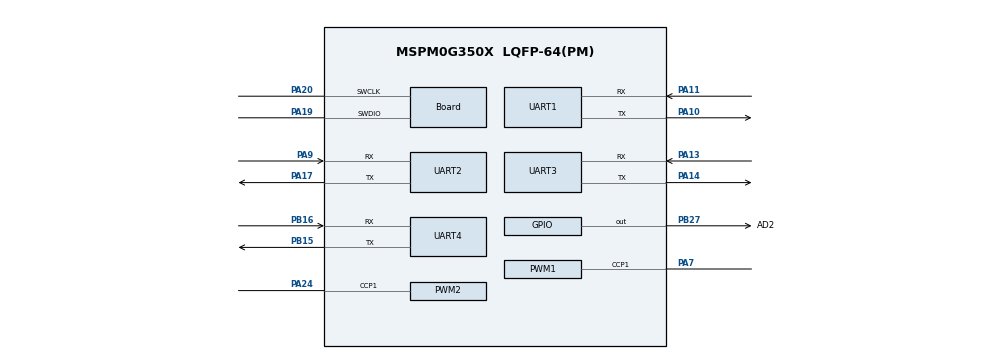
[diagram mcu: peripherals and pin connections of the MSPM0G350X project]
/**
 * @cliArgs --device "MSPM0G350X" --package "LQFP-64(PM)" --part "Default" --product "mspm0_sdk@1.30.00.03"
 * @versions {"tool":"1.19.0+3426"}
 */

/**
 * Import the modules used in this configuration.
 */
const ADC12         = scripting.addModule("/ti/driverlib/ADC12", {}, false);
const ADC121        = ADC12.addInstance();
const ADC122        = ADC12.addInstance();
const GPIO          = scripting.addModule("/ti/driverlib/GPIO", {}, false);
const GPIO1         = GPIO.addInstance();
const GPIO2         = GPIO.addInstance();
const GPIO3         = GPIO.addInstance();
const GPIO4         = GPIO.addInstance();
const GPIO5         = GPIO.addInstance();
const PWM           = scripting.addModule("/ti/driverlib/PWM", {}, false);
const PWM1          = PWM.addInstance();
const PWM2          = PWM.addInstance();
const SYSCTL        = scripting.addModule("/ti/driverlib/SYSCTL");
const SYSTICK       = scripting.addModule("/ti/driverlib/SYSTICK");
const TIMER         = scripting.addModule("/ti/driverlib/TIMER", {}, false);
const TIMER1        = TIMER.addInstance();
const TIMER2        = TIMER.addInstance();
const TIMER3        = TIMER.addInstance();
const TIMER4        = TIMER.addInstance();
const UART          = scripting.addModule("/ti/driverlib/UART", {}, false);
const UART1         = UART.addInstance();
const UART2         = UART.addInstance();
const UART3         = UART.addInstance();
const UART4         = UART.addInstance();
const ProjectConfig = scripting.addModule("/ti/project_config/ProjectConfig");

/**
 * Write custom configuration values to the imported modules.
 */
const divider6       = system.clockTree["PLL_CLK2X_DIV"];
divider6.divideValue = 4;

const divider7       = system.clockTree["PLL_PDIV"];
divider7.divideValue = 2;

const divider9       = system.clockTree["UDIV"];
divider9.divideValue = 2;

const multiplier2         = system.clockTree["PLL_QDIV"];
multiplier2.multiplyValue = 10;

const mux8       = system.clockTree["HSCLKMUX"];
mux8.inputSelect = "HSCLKMUX_SYSPLL2X";

ADC121.$name                             = "ADC_GRAY_SCALE";
ADC121.adcMem0_name                      = "ADC_CH0";
ADC121.sampClkDiv                        = "DL_ADC12_CLOCK_DIVIDE_8";
ADC121.repeatMode                        = true;
ADC121.sampleTime0                       = "3 ms";
ADC121.peripheral.$assign                = "ADC0";
ADC121.peripheral.adcPin0.$assign        = "PA27";
ADC121.adcPin0Config.hideOutputInversion = scripting.forceWrite(false);
ADC121.adcPin0Config.$name               = "ti_driverlib_gpio_GPIOPinGeneric8";

ADC122.adcMem0_name        = "ADC_CH0";
ADC122.sampClkDiv          = "DL_ADC12_CLOCK_DIVIDE_8";
ADC122.repeatMode          = true;
ADC122.$name               = "ADC_BUTTON";
ADC122.adcMem0chansel      = "DL_ADC12_INPUT_CHAN_8";
ADC122.peripheral.$assign  = "ADC1";
ADC122.adcPin8Config.$name = "ti_driverlib_gpio_GPIOPinGeneric4";

const Board                       = scripting.addModule("/ti/driverlib/Board", {}, false);
Board.peripheral.$assign          = "DEBUGSS";
Board.peripheral.swclkPin.$assign = "PA20";
Board.peripheral.swdioPin.$assign = "PA19";

GPIO1.$name                              = "REMINDER";
GPIO1.associatedPins.create(3);
GPIO1.associatedPins[0].$name            = "LED";
GPIO1.associatedPins[0].ioStructure      = "SD";
GPIO1.associatedPins[0].assignedPin      = "22";
GPIO1.associatedPins[0].assignedPort     = "PORTB";
GPIO1.associatedPins[0].internalResistor = "PULL_UP";
GPIO1.associatedPins[1].$name            = "BUZZ";
GPIO1.associatedPins[1].ioStructure      = "SD";
GPIO1.associatedPins[1].internalResistor = "PULL_UP";
GPIO1.associatedPins[1].assignedPort     = "PORTA";
GPIO1.associatedPins[1].assignedPin      = "29";
GPIO1.associatedPins[2].$name            = "LAZER";
GPIO1.associatedPins[2].ioStructure      = "SD";

GPIO2.port                               = "PORTB";
GPIO2.$name                              = "ENCODER_R";
GPIO2.associatedPins.create(2);
GPIO2.associatedPins[0].direction        = "INPUT";
GPIO2.associatedPins[0].ioStructure      = "SD";
GPIO2.associatedPins[0].interruptEn      = true;
GPIO2.associatedPins[0].internalResistor = "PULL_UP";
GPIO2.associatedPins[0].assignedPin      = "17";
GPIO2.associatedPins[0].polarity         = "RISE_FALL";
GPIO2.associatedPins[0].$name            = "R_A";
GPIO2.associatedPins[1].direction        = "INPUT";
GPIO2.associatedPins[1].ioStructure      = "SD";
GPIO2.associatedPins[1].interruptEn      = true;
GPIO2.associatedPins[1].internalResistor = "PULL_UP";
GPIO2.associatedPins[1].assignedPin      = "18";
GPIO2.associatedPins[1].polarity         = "RISE_FALL";
GPIO2.associatedPins[1].$name            = "R_B";

GPIO3.port                               = "PORTB";
GPIO3.$name                              = "ENCODER_L";
GPIO3.associatedPins.create(2);
GPIO3.associatedPins[0].direction        = "INPUT";
GPIO3.associatedPins[0].ioStructure      = "SD";
GPIO3.associatedPins[0].interruptEn      = true;
GPIO3.associatedPins[0].internalResistor = "PULL_UP";
GPIO3.associatedPins[0].assignedPin      = "21";
GPIO3.associatedPins[0].polarity         = "RISE_FALL";
GPIO3.associatedPins[0].$name            = "L_A";
GPIO3.associatedPins[1].direction        = "INPUT";
GPIO3.associatedPins[1].ioStructure      = "SD";
GPIO3.associatedPins[1].interruptEn      = true;
GPIO3.associatedPins[1].internalResistor = "PULL_UP";
GPIO3.associatedPins[1].assignedPin      = "11";
GPIO3.associatedPins[1].polarity         = "RISE_FALL";
GPIO3.associatedPins[1].$name            = "L_B";

GPIO4.$name                              = "MOTOR_DRV";
GPIO4.associatedPins.create(5);
GPIO4.associatedPins[0].ioStructure      = "SD";
GPIO4.associatedPins[0].internalResistor = "PULL_UP";
GPIO4.associatedPins[0].$name            = "STBY";
GPIO4.associatedPins[0].assignedPort     = "PORTB";
GPIO4.associatedPins[0].assignedPin      = "14";
GPIO4.associatedPins[1].ioStructure      = "SD";
GPIO4.associatedPins[1].internalResistor = "PULL_UP";
GPIO4.associatedPins[1].assignedPort     = "PORTB";
GPIO4.associatedPins[1].$name            = "L_IN1";
GPIO4.associatedPins[1].assignedPin      = "1";
GPIO4.associatedPins[2].ioStructure      = "SD";
GPIO4.associatedPins[2].internalResistor = "PULL_UP";
GPIO4.associatedPins[2].$name            = "L_IN2";
GPIO4.associatedPins[2].assignedPin      = "0";
GPIO4.associatedPins[2].assignedPort     = "PORTB";
GPIO4.associatedPins[3].ioStructure      = "SD";
GPIO4.associatedPins[3].internalResistor = "PULL_UP";
GPIO4.associatedPins[3].$name            = "R_IN1";
GPIO4.associatedPins[3].assignedPort     = "PORTA";
GPIO4.associatedPins[3].assignedPin      = "16";
GPIO4.associatedPins[4].ioStructure      = "SD";
GPIO4.associatedPins[4].internalResistor = "PULL_UP";
GPIO4.associatedPins[4].$name            = "R_IN2";
GPIO4.associatedPins[4].assignedPort     = "PORTB";
GPIO4.associatedPins[4].assignedPin      = "19";

GPIO5.$name                          = "GRAY_SCALE";
GPIO5.associatedPins.create(3);
GPIO5.associatedPins[0].$name        = "AD0";
GPIO5.associatedPins[0].assignedPort = "PORTB";
GPIO5.associatedPins[0].assignedPin  = "23";
GPIO5.associatedPins[1].$name        = "AD1";
GPIO5.associatedPins[1].assignedPort = "PORTB";
GPIO5.associatedPins[1].assignedPin  = "26";
GPIO5.associatedPins[2].$name        = "AD2";
GPIO5.associatedPins[2].assignedPort = "PORTB";
GPIO5.associatedPins[2].assignedPin  = "27";
GPIO5.associatedPins[2].pin.$assign  = "PB27";

PWM1.timerStartTimer                    = true;
PWM1.pwmMode                            = "EDGE_ALIGN_UP";
PWM1.clockPrescale                      = 2;
PWM1.timerCount                         = 1600;
PWM1.ccIndex                            = [1];
PWM1.$name                              = "PWM_MOTOR_R";
PWM1.peripheral.$assign                 = "TIMA0";
PWM1.peripheral.ccp1Pin.$assign         = "PA7";
PWM1.ccp1PinConfig.direction            = scripting.forceWrite("OUTPUT");
PWM1.ccp1PinConfig.hideOutputInversion  = scripting.forceWrite(false);
PWM1.ccp1PinConfig.onlyInternalResistor = scripting.forceWrite(false);
PWM1.ccp1PinConfig.passedPeripheralType = scripting.forceWrite("Digital");
PWM1.ccp1PinConfig.$name                = "ti_driverlib_gpio_GPIOPinGeneric5";
PWM1.PWM_CHANNEL_1.$name                = "ti_driverlib_pwm_PWMTimerCC0";

PWM2.clockPrescale                      = 2;
PWM2.timerCount                         = 1600;
PWM2.timerStartTimer                    = true;
PWM2.pwmMode                            = "EDGE_ALIGN_UP";
PWM2.ccIndex                            = [1];
PWM2.$name                              = "PWM_MOTOR_L";
PWM2.peripheral.$assign                 = "TIMA1";
PWM2.peripheral.ccp1Pin.$assign         = "PA24";
PWM2.ccp1PinConfig.direction            = scripting.forceWrite("OUTPUT");
PWM2.ccp1PinConfig.hideOutputInversion  = scripting.forceWrite(false);
PWM2.ccp1PinConfig.onlyInternalResistor = scripting.forceWrite(false);
PWM2.ccp1PinConfig.passedPeripheralType = scripting.forceWrite("Digital");
PWM2.ccp1PinConfig.$name                = "ti_driverlib_gpio_GPIOPinGeneric7";
PWM2.PWM_CHANNEL_1.$name                = "ti_driverlib_pwm_PWMTimerCC2";

SYSCTL.clockTreeEn = true;

SYSTICK.periodEnable      = true;
SYSTICK.interruptEnable   = true;
SYSTICK.interruptPriority = "0";
SYSTICK.systickEnable     = true;
SYSTICK.period            = 80000;

TIMER1.timerStartTimer    = true;
TIMER1.timerMode          = "PERIODIC";
TIMER1.timerClkDiv        = 8;
TIMER1.interrupts         = ["ZERO"];
TIMER1.timerClkPrescale   = 40;
TIMER1.$name              = "ENCODER_TIMER";
TIMER1.timerPeriod        = "30 ms";
TIMER1.peripheral.$assign = "TIMG7";

TIMER2.timerClkDiv        = 8;
TIMER2.timerClkPrescale   = 40;
TIMER2.timerMode          = "PERIODIC";
TIMER2.timerStartTimer    = true;
TIMER2.interrupts         = ["ZERO"];
TIMER2.$name              = "PID_TIMER";
TIMER2.timerPeriod        = "30 ms";
TIMER2.peripheral.$assign = "TIMG6";

TIMER3.timerStartTimer  = true;
TIMER3.interrupts       = ["ZERO"];
TIMER3.timerMode        = "PERIODIC";
TIMER3.$name            = "READ_TIMER";
TIMER3.timerClkDiv      = 8;
TIMER3.timerClkPrescale = 50;
TIMER3.timerPeriod      = "5 ms";

TIMER4.$name            = "PTZ_TIMER";
TIMER4.timerStartTimer  = true;
TIMER4.timerMode        = "PERIODIC";
TIMER4.interrupts       = ["ZERO"];
TIMER4.timerClkDiv      = 8;
TIMER4.timerClkPrescale = 5;
TIMER4.timerPeriod      = "6 ms";

UART1.$name                    = "UART_0";
UART1.enableDMARX              = false;
UART1.enableDMATX              = false;
UART1.enabledInterrupts        = ["RX"];
UART1.rxFifoThreshold          = "DL_UART_RX_FIFO_LEVEL_ONE_ENTRY";
UART1.txFifoThreshold          = "DL_UART_TX_FIFO_LEVEL_3_4_EMPTY";
UART1.enableFIFO               = true;
UART1.peripheral.$assign       = "UART0";
UART1.peripheral.rxPin.$assign = "PA11";
UART1.peripheral.txPin.$assign = "PA10";
UART1.txPinConfig.$name        = "ti_driverlib_gpio_GPIOPinGeneric0";
UART1.rxPinConfig.$name        = "ti_driverlib_gpio_GPIOPinGeneric1";

UART2.$name                    = "UART_1";
UART2.rxFifoThreshold          = "DL_UART_RX_FIFO_LEVEL_ONE_ENTRY";
UART2.txFifoThreshold          = "DL_UART_TX_FIFO_LEVEL_3_4_EMPTY";
UART2.enabledInterrupts        = ["RX"];
UART2.peripheral.$assign       = "UART1";
UART2.peripheral.rxPin.$assign = "PA9";
UART2.peripheral.txPin.$assign = "PA17";
UART2.txPinConfig.$name        = "ti_driverlib_gpio_GPIOPinGeneric2";
UART2.rxPinConfig.$name        = "ti_driverlib_gpio_GPIOPinGeneric3";

UART3.$name                    = "UART_2";
UART3.enabledInterrupts        = ["RX"];
UART3.targetBaudRate           = 115200;
UART3.interruptPriority        = "0";
UART3.peripheral.rxPin.$assign = "PA13";
UART3.peripheral.txPin.$assign = "PA14";
UART3.txPinConfig.$name        = "ti_driverlib_gpio_GPIOPinGeneric9";
UART3.rxPinConfig.$name        = "ti_driverlib_gpio_GPIOPinGeneric10";

UART4.$name                    = "UART_3";
UART4.enabledInterrupts        = ["RX"];
UART4.peripheral.$assign       = "UART2";
UART4.peripheral.rxPin.$assign = "PB16";
UART4.peripheral.txPin.$assign = "PB15";
UART4.txPinConfig.$name        = "ti_driverlib_gpio_GPIOPinGeneric11";
UART4.rxPinConfig.$name        = "ti_driverlib_gpio_GPIOPinGeneric12";

ProjectConfig.deviceSpin = "MSPM0G3507";
scripting.suppress("Migrating requires going through the Switch Board or Device menu in the Device View section\\.", ProjectConfig, "deviceSpin");

/**
 * Pinmux solution for unlocked pins/peripherals. This ensures that minor changes to the automatic solver in a future
 * version of the tool will not impact the pinmux you originally saw.  These lines can be completely deleted in order to
 * re-solve from scratch.
 */
ADC122.peripheral.adcPin8.$suggestSolution   = "PA22";
GPIO1.associatedPins[0].pin.$suggestSolution = "PB22";
GPIO1.associatedPins[1].pin.$suggestSolution = "PA29";
GPIO1.associatedPins[2].pin.$suggestSolution = "PB13";
GPIO2.associatedPins[0].pin.$suggestSolution = "PB17";
GPIO2.associatedPins[1].pin.$suggestSolution = "PB18";
GPIO3.associatedPins[0].pin.$suggestSolution = "PB21";
GPIO3.associatedPins[1].pin.$suggestSolution = "PB11";
GPIO4.associatedPins[0].pin.$suggestSolution = "PB14";
GPIO4.associatedPins[1].pin.$suggestSolution = "PB1";
GPIO4.associatedPins[2].pin.$suggestSolution = "PB0";
GPIO4.associatedPins[3].pin.$suggestSolution = "PA16";
GPIO4.associatedPins[4].pin.$suggestSolution = "PB19";
GPIO5.associatedPins[0].pin.$suggestSolution = "PB23";
GPIO5.associatedPins[1].pin.$suggestSolution = "PB26";
TIMER3.peripheral.$suggestSolution           = "TIMG8";
TIMER4.peripheral.$suggestSolution           = "TIMG0";
UART3.peripheral.$suggestSolution            = "UART3";
